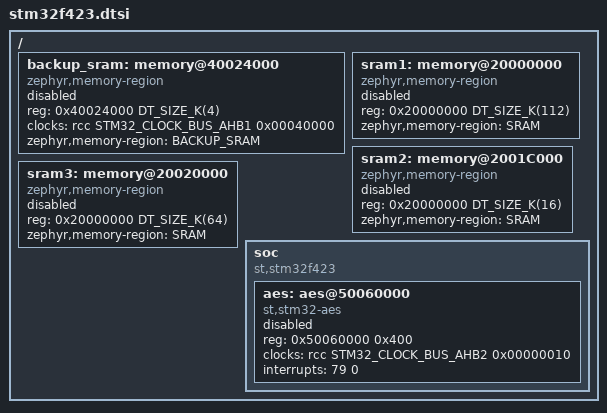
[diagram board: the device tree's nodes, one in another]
/*
 * Copyright (c) 2022 Richard Osterloh
 *
 * SPDX-License-Identifier: Apache-2.0
 */

#include <st/f4/stm32f413.dtsi>

/ {

	backup_sram: memory@40024000 {
		compatible = "zephyr,memory-region", "st,stm32-backup-sram";
		reg = <0x40024000 DT_SIZE_K(4)>;
		clocks = <&rcc STM32_CLOCK_BUS_AHB1 0x00040000>;
		zephyr,memory-region = "BACKUP_SRAM";
		status = "disabled";
	};

	sram1: memory@20000000 {
		compatible = "zephyr,memory-region", "st,stm32-sram";
		reg = <0x20000000 DT_SIZE_K(112)>;
		zephyr,memory-region = "SRAM";
		status = "disabled";
	};

	sram2: memory@2001C000 {
		compatible = "zephyr,memory-region", "st,stm32-sram";
		reg = <0x20000000 DT_SIZE_K(16)>;
		zephyr,memory-region = "SRAM";
		status = "disabled";
	};

	sram3: memory@20020000 {
		compatible = "zephyr,memory-region", "st,stm32-sram";
		reg = <0x20000000 DT_SIZE_K(64)>;
		zephyr,memory-region = "SRAM";
		status = "disabled";
	};

	soc {
		compatible = "st,stm32f423", "st,stm32f4", "simple-bus";

		aes: aes@50060000 {
			compatible = "st,stm32-aes";
			reg = <0x50060000 0x400>;
			clocks = <&rcc STM32_CLOCK_BUS_AHB2 0x00000010>;
			interrupts = <79 0>;
			status = "disabled";
		};
	};
};
